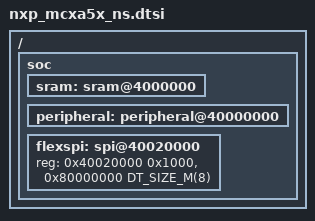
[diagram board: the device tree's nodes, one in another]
/*
 * Copyright 2025 NXP
 *
 * SPDX-License-Identifier: Apache-2.0
 */

#include <mem.h>
#include <arm/armv8-m.dtsi>

/ {
	soc {
		sram: sram@4000000 {
			ranges = <0x4000000 0x4000000 0x20000000>;
		};

		peripheral: peripheral@40000000 {
			ranges = <0x0 0x40000000 0x10000000>;
		};

		flexspi: spi@40020000 {
			reg = <0x40020000 0x1000>, <0x80000000 DT_SIZE_M(8)>;
		};
	};
};

#include "nxp_mcxa5x_common.dtsi"
